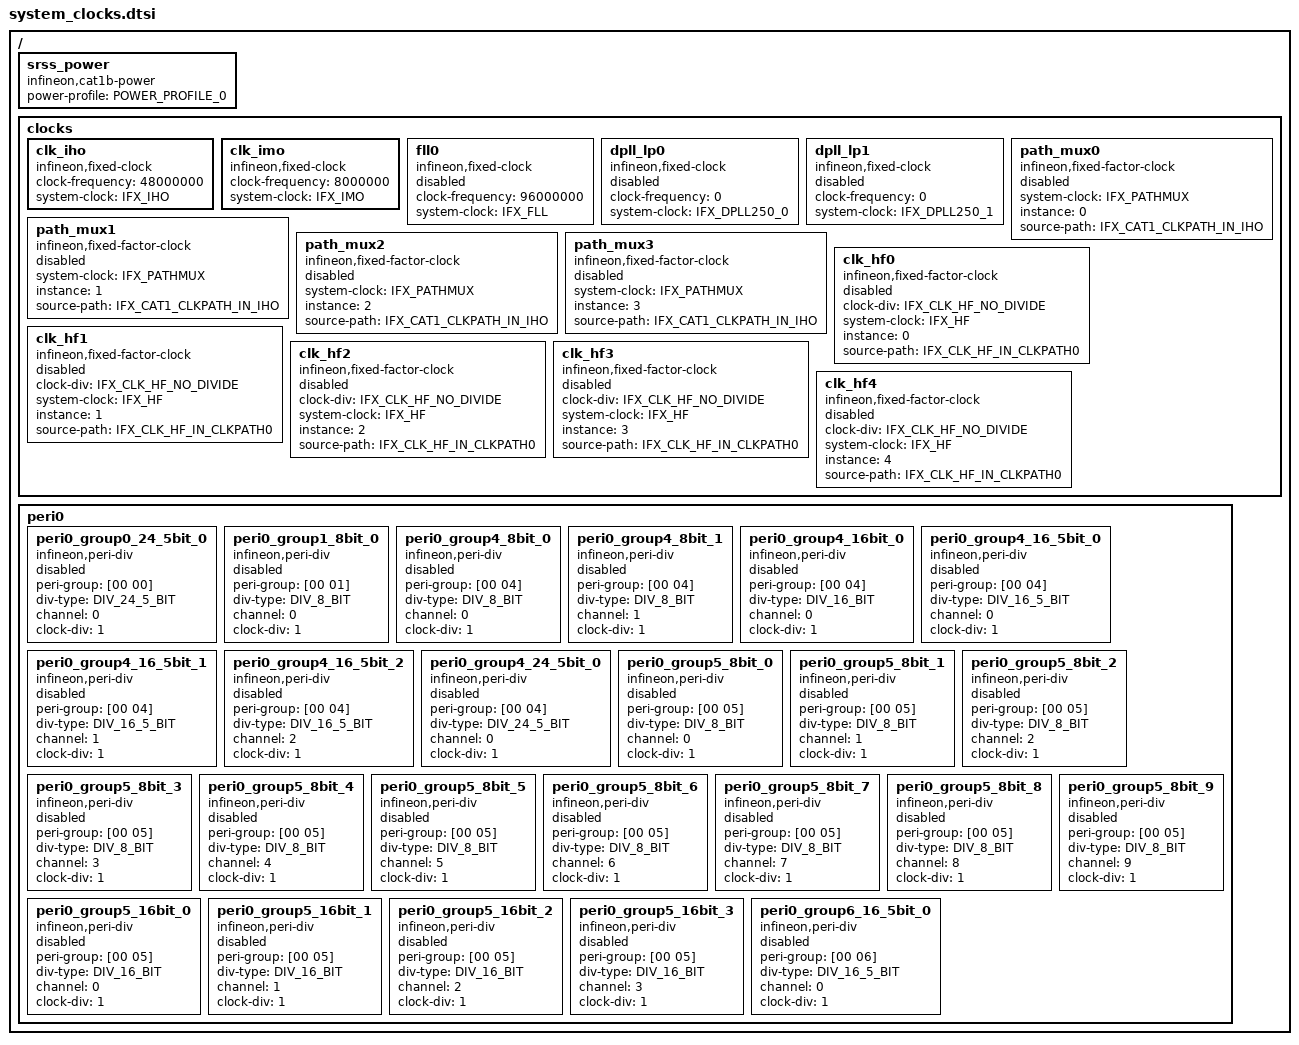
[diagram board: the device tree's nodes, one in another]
/*
 * Copyright (c) 2025 Cypress Semiconductor Corporation (an Infineon company) or
 * an affiliate of Cypress Semiconductor Corporation
 *
 * SPDX-License-Identifier: Apache-2.0
 */

#define DIV_8_BIT    00
#define DIV_16_BIT	 01
#define DIV_16_5_BIT 02
#define DIV_24_5_BIT 03

#include <dt-bindings/clock/ifx_clock_source_common.h>
#include <dt-bindings/clock/ifx_clock_source_psc3xx.h>

/ {
	srss_power: srss_power {
		#clock-cells = <0>;
		compatible = "infineon,cat1b-power";
		power-profile = "POWER_PROFILE_0";
		status = "okay";
	};

	clocks {
		/* iho */
		clk_iho: clk_iho {
			#clock-cells = <0>;
			compatible = "infineon,fixed-clock";
			clock-frequency = <48000000>;
			system-clock = <IFX_IHO>;
			status = "okay";
		};

		/* imo */
		clk_imo: clk_imo {
			#clock-cells = <0>;
			compatible = "infineon,fixed-clock";
			clock-frequency = <8000000>;
			system-clock = <IFX_IMO>;
			status = "okay";
		};

		/* fll */
		fll0: fll0 {
			#clock-cells = <0>;
			compatible = "infineon,fixed-clock";
			clock-frequency = <96000000>;
			system-clock = <IFX_FLL>;
			status = "disabled";
		};

		dpll_lp0: dpll_lp0 {
			#clock-cells = <0>;
			compatible = "infineon,fixed-clock";
			clock-frequency = <0>;
			system-clock = <IFX_DPLL250_0>;
			status = "disabled";
		};

		dpll_lp1: dpll_lp1 {
			#clock-cells = <0>;
			compatible = "infineon,fixed-clock";
			clock-frequency = <0>;
			system-clock = <IFX_DPLL250_1>;
			status = "disabled";
		};

		/* path mux0 */
		path_mux0: path_mux0 {
			#clock-cells = <0>;
			compatible = "infineon,fixed-factor-clock";
			system-clock = <IFX_PATHMUX>;
			instance = <0>;
			source-path = <IFX_CAT1_CLKPATH_IN_IHO>;
			status = "disabled";
		};

		/* path mux1 */
		path_mux1: path_mux1 {
			#clock-cells = <0>;
			compatible = "infineon,fixed-factor-clock";
			system-clock = <IFX_PATHMUX>;
			instance = <1>;
			source-path = <IFX_CAT1_CLKPATH_IN_IHO>;
			status = "disabled";
		};

		/* path mux2 */
		path_mux2: path_mux2 {
			#clock-cells = <0>;
			compatible = "infineon,fixed-factor-clock";
			system-clock = <IFX_PATHMUX>;
			instance = <2>;
			source-path = <IFX_CAT1_CLKPATH_IN_IHO>;
			status = "disabled";
		};

		/* path mux3 */
		path_mux3: path_mux3 {
			#clock-cells = <0>;
			compatible = "infineon,fixed-factor-clock";
			system-clock = <IFX_PATHMUX>;
			instance = <3>;
			source-path = <IFX_CAT1_CLKPATH_IN_IHO>;
			status = "disabled";
		};

		/* clk_hf0 */
		clk_hf0: clk_hf0 {
			#clock-cells = <0>;
			compatible = "infineon,fixed-factor-clock";
			clock-div = <IFX_CLK_HF_NO_DIVIDE>;
			system-clock = <IFX_HF>;
			instance = <0>;
			source-path = <IFX_CLK_HF_IN_CLKPATH0>;
			status = "disabled";
		};

		/* clk_hf1 */
		clk_hf1: clk_hf1 {
			#clock-cells = <0>;
			compatible = "infineon,fixed-factor-clock";
			clock-div = <IFX_CLK_HF_NO_DIVIDE>;
			system-clock = <IFX_HF>;
			instance = <1>;
			source-path = <IFX_CLK_HF_IN_CLKPATH0>;
			status = "disabled";
		};

		/* clk_hf2 */
		clk_hf2: clk_hf2 {
			#clock-cells = <0>;
			compatible = "infineon,fixed-factor-clock";
			clock-div = <IFX_CLK_HF_NO_DIVIDE>;
			system-clock = <IFX_HF>;
			instance = <2>;
			source-path = <IFX_CLK_HF_IN_CLKPATH0>;
			status = "disabled";
		};

		/* clk_hf3 */
		clk_hf3: clk_hf3 {
			#clock-cells = <0>;
			compatible = "infineon,fixed-factor-clock";
			clock-div = <IFX_CLK_HF_NO_DIVIDE>;
			system-clock = <IFX_HF>;
			instance = <3>;
			source-path = <IFX_CLK_HF_IN_CLKPATH0>;
			status = "disabled";
		};

		/* clk_hf4 */
		clk_hf4: clk_hf4 {
			#clock-cells = <0>;
			compatible = "infineon,fixed-factor-clock";
			clock-div = <IFX_CLK_HF_NO_DIVIDE>;
			system-clock = <IFX_HF>;
			instance = <4>;
			source-path = <IFX_CLK_HF_IN_CLKPATH0>;
			status = "disabled";
		};
	};

	peri0: peri0 {
		/* Peripheral 0, Clock Group 0 */
		/* 24.5-bit */
		peri0_group0_24_5bit_0: peri0_group0_24_5bit_0 {
			#clock-cells = <0>;
			compatible = "infineon,peri-div";
			peri-group = [00 00]; /* inst#, group# */
			div-type = <DIV_24_5_BIT>;
			channel = <0>;
			clock-div = <1>;
			status = "disabled";
		};

		/* Peripheral 0, Clock Group 1 */
		/* 8-bit */
		peri0_group1_8bit_0: peri0_group1_8bit_0 {
			#clock-cells = <0>;
			compatible = "infineon,peri-div";
			peri-group = [00 01]; /* inst#, group# */
			div-type = <DIV_8_BIT>;
			channel = <0>;
			clock-div = <1>;
			status = "disabled";
		};

		/* Peripheral 0, Clock Group 4 */
		/* 8-bit */
		peri0_group4_8bit_0: peri0_group4_8bit_0 {
			#clock-cells = <0>;
			compatible = "infineon,peri-div";
			peri-group = [00 04]; /* inst#, group# */
			div-type = <DIV_8_BIT>;
			channel = <0>;
			clock-div = <1>;
			status = "disabled";
		};

		peri0_group4_8bit_1: peri0_group4_8bit_1 {
			#clock-cells = <0>;
			compatible = "infineon,peri-div";
			peri-group = [00 04]; /* inst#, group# */
			div-type = <DIV_8_BIT>;
			channel = <1>;
			clock-div = <1>;
			status = "disabled";
		};

		/* 16-bit */
		peri0_group4_16bit_0: peri0_group4_16bit_0 {
			#clock-cells = <0>;
			compatible = "infineon,peri-div";
			peri-group = [00 04]; /* inst#, group# */
			div-type = <DIV_16_BIT>;
			channel = <0>;
			clock-div = <1>;
			status = "disabled";
		};

		/* 16.5-bit */
		peri0_group4_16_5bit_0: peri0_group4_16_5bit_0 {
			#clock-cells = <0>;
			compatible = "infineon,peri-div";
			peri-group = [00 04]; /* inst#, group# */
			div-type = <DIV_16_5_BIT>;
			channel = <0>;
			clock-div = <1>;
			status = "disabled";
		};

		peri0_group4_16_5bit_1: peri0_group4_16_5bit_1 {
			#clock-cells = <0>;
			compatible = "infineon,peri-div";
			peri-group = [00 04]; /* inst#, group# */
			div-type = <DIV_16_5_BIT>;
			channel = <1>;
			clock-div = <1>;
			status = "disabled";
		};

		peri0_group4_16_5bit_2: peri0_group4_16_5bit_2 {
			#clock-cells = <0>;
			compatible = "infineon,peri-div";
			peri-group = [00 04]; /* inst#, group# */
			div-type = <DIV_16_5_BIT>;
			channel = <2>;
			clock-div = <1>;
			status = "disabled";
		};

		/* 24.5-bit */
		peri0_group4_24_5bit_0: peri0_group4_24_5bit_0 {
			#clock-cells = <0>;
			compatible = "infineon,peri-div";
			peri-group = [00 04]; /* inst#, group# */
			div-type = <DIV_24_5_BIT>;
			channel = <0>;
			clock-div = <1>;
			status = "disabled";
		};

		/* Peripheral 0, Clock Group 5 */
		/* 8-bit */
		peri0_group5_8bit_0: peri0_group5_8bit_0 {
			#clock-cells = <0>;
			compatible = "infineon,peri-div";
			peri-group = [00 05]; /* inst#, group# */
			div-type = <DIV_8_BIT>;
			channel = <0>;
			clock-div = <1>;
			status = "disabled";
		};

		peri0_group5_8bit_1: peri0_group5_8bit_1 {
			#clock-cells = <0>;
			compatible = "infineon,peri-div";
			peri-group = [00 05]; /* inst#, group# */
			div-type = <DIV_8_BIT>;
			channel = <1>;
			clock-div = <1>;
			status = "disabled";
		};

		peri0_group5_8bit_2: peri0_group5_8bit_2 {
			#clock-cells = <0>;
			compatible = "infineon,peri-div";
			peri-group = [00 05]; /* inst#, group# */
			div-type = <DIV_8_BIT>;
			channel = <2>;
			clock-div = <1>;
			status = "disabled";
		};

		peri0_group5_8bit_3: peri0_group5_8bit_3 {
			#clock-cells = <0>;
			compatible = "infineon,peri-div";
			peri-group = [00 05]; /* inst#, group# */
			div-type = <DIV_8_BIT>;
			channel = <3>;
			clock-div = <1>;
			status = "disabled";
		};

		peri0_group5_8bit_4: peri0_group5_8bit_4 {
			#clock-cells = <0>;
			compatible = "infineon,peri-div";
			peri-group = [00 05]; /* inst#, group# */
			div-type = <DIV_8_BIT>;
			channel = <4>;
			clock-div = <1>;
			status = "disabled";
		};

		peri0_group5_8bit_5: peri0_group5_8bit_5 {
			#clock-cells = <0>;
			compatible = "infineon,peri-div";
			peri-group = [00 05]; /* inst#, group# */
			div-type = <DIV_8_BIT>;
			channel = <5>;
			clock-div = <1>;
			status = "disabled";
		};

		peri0_group5_8bit_6: peri0_group5_8bit_6 {
			#clock-cells = <0>;
			compatible = "infineon,peri-div";
			peri-group = [00 05]; /* inst#, group# */
			div-type = <DIV_8_BIT>;
			channel = <6>;
			clock-div = <1>;
			status = "disabled";
		};

		peri0_group5_8bit_7: peri0_group5_8bit_7 {
			#clock-cells = <0>;
			compatible = "infineon,peri-div";
			peri-group = [00 05]; /* inst#, group# */
			div-type = <DIV_8_BIT>;
			channel = <7>;
			clock-div = <1>;
			status = "disabled";
		};

		peri0_group5_8bit_8: peri0_group5_8bit_8 {
			#clock-cells = <0>;
			compatible = "infineon,peri-div";
			peri-group = [00 05]; /* inst#, group# */
			div-type = <DIV_8_BIT>;
			channel = <8>;
			clock-div = <1>;
			status = "disabled";
		};

		peri0_group5_8bit_9: peri0_group5_8bit_9 {
			#clock-cells = <0>;
			compatible = "infineon,peri-div";
			peri-group = [00 05]; /* inst#, group# */
			div-type = <DIV_8_BIT>;
			channel = <9>;
			clock-div = <1>;
			status = "disabled";
		};

		/* 16-bit */
		peri0_group5_16bit_0: peri0_group5_16bit_0 {
			#clock-cells = <0>;
			compatible = "infineon,peri-div";
			peri-group = [00 05]; /* inst#, group# */
			div-type = <DIV_16_BIT>;
			channel = <0>;
			clock-div = <1>;
			status = "disabled";
		};

		peri0_group5_16bit_1: peri0_group5_16bit_1 {
			#clock-cells = <0>;
			compatible = "infineon,peri-div";
			peri-group = [00 05]; /* inst#, group# */
			div-type = <DIV_16_BIT>;
			channel = <1>;
			clock-div = <1>;
			status = "disabled";
		};

		peri0_group5_16bit_2: peri0_group5_16bit_2 {
			#clock-cells = <0>;
			compatible = "infineon,peri-div";
			peri-group = [00 05]; /* inst#, group# */
			div-type = <DIV_16_BIT>;
			channel = <2>;
			clock-div = <1>;
			status = "disabled";
		};

		peri0_group5_16bit_3: peri0_group5_16bit_3 {
			#clock-cells = <0>;
			compatible = "infineon,peri-div";
			peri-group = [00 05]; /* inst#, group# */
			div-type = <DIV_16_BIT>;
			channel = <3>;
			clock-div = <1>;
			status = "disabled";
		};

		/* Peripheral 0, Clock Group 6 */
		/* 16.5-bit */
		peri0_group6_16_5bit_0: peri0_group6_16_5bit_0 {
			#clock-cells = <0>;
			compatible = "infineon,peri-div";
			peri-group = [00 06]; /* inst#, group# */
			div-type = <DIV_16_5_BIT>;
			channel = <0>;
			clock-div = <1>;
			status = "disabled";
		};
	};
};
